# SP28038 register map
Vendor: NXP Semiconductors; Series: SP2083X; File version: 1.0
CPU: CM4 r0p1, little endian, no MPU, FPU, VTOR, 4 interrupt priority bits
Registers are 32-bit, read-write, reset 0x0 unless marked. A register's access mark holds for its fields unless they carry their own. Offsets are from the block's base; [hi:lo] are bit positions; {n}, {i} and the like mark numbered series.

## LPUART0 — Universal Asynchronous Receiver/Transmitter
Base 0x400C4000; register names take the prefix LPUART0_
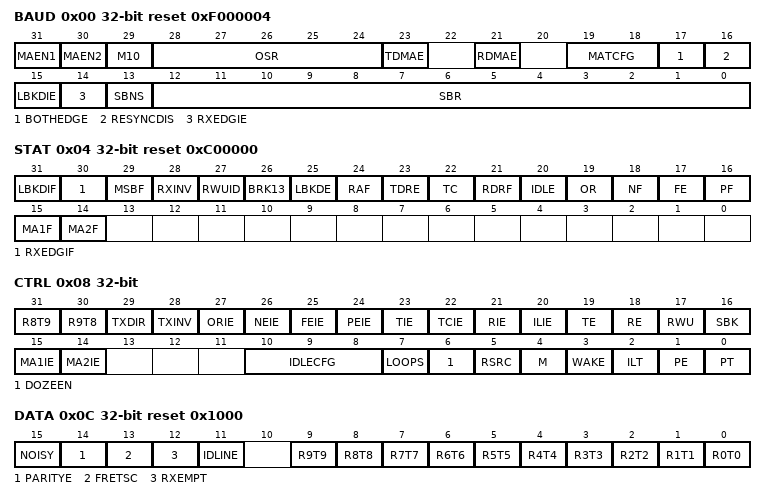
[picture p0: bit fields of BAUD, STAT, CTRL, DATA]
0x00 BAUD reset 0xF000004 — LPUART Baud Rate Register
  [31] MAEN1 — Match Address Mode Enable 1
    0=Normal operation; 1=Enables automatic address matching or data matching mode for MATCH[MA1]
  [30] MAEN2 — Match Address Mode Enable 2
    0=Normal operation; 1=Enables automatic address matching or data matching mode for MATCH[MA2]
  [29] M10 — 10-bit Mode select
    0=Receiver and transmitter use 8-bit or 9-bit data characters; 1=Receiver and transmitter use 10-bit data characters
  [28:24] OSR — Over Sampling Ratio
  [23] TDMAE — Transmitter DMA Enable
    0=DMA request disabled; 1=DMA request enabled
  [21] RDMAE — Receiver Full DMA Enable
    0=DMA request disabled; 1=DMA request enabled
  [19:18] MATCFG — Match Configuration
    0=Address Match Wakeup; 1=Idle Match Wakeup; 2=Match On and Match Off; 3=Enables RWU on Data Match and Match On/Off for transmitter CTS input
  [17] BOTHEDGE — Both Edge Sampling
    0=Receiver samples input data using the rising edge of the baud rate clock; 1=Receiver samples input data using the rising and falling edge of the baud rate clock
  [16] RESYNCDIS — Resynchronization Disable
    0=Resynchronization during received data word is supported; 1=Resynchronization during received data word is disabled
  [15] LBKDIE — LIN Break Detect Interrupt Enable
    0=Hardware interrupts from LPUART_STAT[LBKDIF] disabled (use polling); 1=Hardware interrupt requested when LPUART_STAT[LBKDIF] flag is 1
  [14] RXEDGIE — RX Input Active Edge Interrupt Enable
    0=Hardware interrupts from LPUART_STAT[RXEDGIF] disabled (use polling); 1=Hardware interrupt requested when LPUART_STAT[RXEDGIF] flag is 1
  [13] SBNS — Stop Bit Number Select
    0=One stop bit; 1=Two stop bits
  [12:0] SBR — Baud Rate Modulo Divisor.
0x04 STAT reset 0xC00000 — LPUART Status Register
  [31] LBKDIF — LIN Break Detect Interrupt Flag
    0=No LIN break character has been detected; 1=LIN break character has been detected
  [30] RXEDGIF — LPUART_RX Pin Active Edge Interrupt Flag
    0=No active edge on the receive pin has occurred; 1=An active edge on the receive pin has occurred
  [29] MSBF — MSB First
    0=LSB (bit0) is the first bit that is transmitted following the start bit. Further, the first bit received after the start bit is identified as bit0.; 1=MSB (bit9, bit8, bit7 or bit6) is the first bit that is transmitted following the start bit depending on the setting of CTRL[M], CTRL[PE] and BAUD[M10]. Further, the first bit received after the start bit is identified as bit9, bit8, bit7 or bit6 depending on the setting of CTRL[M] and CTRL[PE].
  [28] RXINV — Receive Data Inversion
    0=Receive data not inverted; 1=Receive data inverted
  [27] RWUID — Receive Wake Up Idle Detect
    0=During receive standby state (RWU = 1), the IDLE bit does not get set upon detection of an idle character. During address match wakeup, the IDLE bit does not get set when an address does not match.; 1=During receive standby state (RWU = 1), the IDLE bit gets set upon detection of an idle character. During address match wakeup, the IDLE bit does get set when an address does not match.
  [26] BRK13 — Break Character Generation Length
    0=Break character is transmitted with length of 10 bit times (if M = 0, SBNS = 0) or 11 (if M = 1, SBNS = 0 or M = 0, SBNS = 1) or 12 (if M = 1, SBNS = 1 or M10 = 1, SNBS = 0) or 13 (if M10 = 1, SNBS = 1); 1=Break character is transmitted with length of 13 bit times (if M = 0, SBNS = 0) or 14 (if M = 1, SBNS = 0 or M = 0, SBNS = 1) or 15 (if M = 1, SBNS = 1 or M10 = 1, SNBS = 0) or 16 (if M10 = 1, SNBS = 1)
  [25] LBKDE — LIN Break Detection Enable
    0=Break character is detected at length 10 bit times (if M = 0, SBNS = 0) or 11 (if M = 1, SBNS = 0 or M = 0, SBNS = 1) or 12 (if M = 1, SBNS = 1 or M10 = 1, SNBS = 0) or 13 (if M10 = 1, SNBS = 1); 1=Break character is detected at length of 11 bit times (if M = 0, SBNS = 0) or 12 (if M = 1, SBNS = 0 or M = 0, SBNS = 1) or 14 (if M = 1, SBNS = 1 or M10 = 1, SNBS = 0) or 15 (if M10 = 1, SNBS = 1)
  [24] RAF ro — Receiver Active Flag
    0=LPUART receiver idle waiting for a start bit; 1=LPUART receiver active (LPUART_RX input not idle)
  [23] TDRE ro — Transmit Data Register Empty Flag
    0=Transmit data buffer full; 1=Transmit data buffer empty
  [22] TC ro — Transmission Complete Flag
    0=Transmitter active (sending data, a preamble, or a break); 1=Transmitter idle (transmission activity complete)
  [21] RDRF ro — Receive Data Register Full Flag
    0=Receive data buffer empty; 1=Receive data buffer full
  [20] IDLE — Idle Line Flag
    0=No idle line detected; 1=Idle line was detected
  [19] OR — Receiver Overrun Flag
    0=No overrun; 1=Receive overrun (new LPUART data lost)
  [18] NF — Noise Flag
    0=No noise detected; 1=Noise detected in the received character in LPUART_DATA
  [17] FE — Framing Error Flag
    0=No framing error detected. This does not guarantee the framing is correct.; 1=Framing error
  [16] PF — Parity Error Flag
    0=No parity error; 1=Parity error
  [15] MA1F — Match 1 Flag
    0=Received data is not equal to MA1; 1=Received data is equal to MA1
  [14] MA2F — Match 2 Flag
    0=Received data is not equal to MA2; 1=Received data is equal to MA2
0x08 CTRL — LPUART Control Register
  [31] R8T9 — Receive Bit 8 / Transmit Bit 9
  [30] R9T8 — Receive Bit 9 / Transmit Bit 8
  [29] TXDIR — LPUART_TX Pin Direction in Single-Wire Mode
    0=LPUART_TX pin is an input in single-wire mode; 1=LPUART_TX pin is an output in single-wire mode
  [28] TXINV — Transmit Data Inversion
    0=Transmit data not inverted; 1=Transmit data inverted
  [27] ORIE — Overrun Interrupt Enable
    0=OR interrupts disabled; use polling; 1=Hardware interrupt requested when OR is set
  [26] NEIE — Noise Error Interrupt Enable
    0=NF interrupts disabled; use polling; 1=Hardware interrupt requested when NF is set
  [25] FEIE — Framing Error Interrupt Enable
    0=FE interrupts disabled; use polling; 1=Hardware interrupt requested when FE is set
  [24] PEIE — Parity Error Interrupt Enable
    0=PF interrupts disabled; use polling); 1=Hardware interrupt requested when PF is set
  [23] TIE — Transmit Interrupt Enable
    0=Hardware interrupts from TDRE disabled; use polling; 1=Hardware interrupt requested when TDRE flag is 1
  [22] TCIE — Transmission Complete Interrupt Enable for
    0=Hardware interrupts from TC disabled; use polling; 1=Hardware interrupt requested when TC flag is 1
  [21] RIE — Receiver Interrupt Enable
    0=Hardware interrupts from RDRF disabled; use polling; 1=Hardware interrupt requested when RDRF flag is 1
  [20] ILIE — Idle Line Interrupt Enable
    0=Hardware interrupts from IDLE disabled; use polling; 1=Hardware interrupt requested when IDLE flag is 1
  [19] TE — Transmitter Enable
    0=Transmitter disabled; 1=Transmitter enabled
  [18] RE — Receiver Enable
    0=Receiver disabled; 1=Receiver enabled
  [17] RWU — Receiver Wakeup Control
    0=Normal receiver operation; 1=LPUART receiver in standby waiting for wakeup condition
  [16] SBK — Send Break
    0=Normal transmitter operation; 1=Queue break character(s) to be sent
  [15] MA1IE — Match 1 Interrupt Enable
    0=MA1F interrupt disabled; 1=MA1F interrupt enabled
  [14] MA2IE — Match 2 Interrupt Enable
    0=MA2F interrupt disabled; 1=MA2F interrupt enabled
  [10:8] IDLECFG — Idle Configuration
    0=1 idle character; 1=2 idle characters; 2=4 idle characters; 3=8 idle characters; 4=16 idle characters; 5=32 idle characters; 6=64 idle characters; 7=128 idle characters
  [7] LOOPS — Loop Mode Select
    0=Normal operation - LPUART_RX and LPUART_TX use separate pins; 1=Loop mode or single-wire mode where transmitter outputs are internally connected to receiver input (see RSRC bit)
  [6] DOZEEN — Doze Enable
    0=LPUART is enabled in Doze mode; 1=LPUART is disabled in Doze mode
  [5] RSRC — Receiver Source Select
    0=Provided LOOPS is set, RSRC is cleared, selects internal loop back mode and the LPUART does not use the LPUART_RX pin; 1=Single-wire LPUART mode where the LPUART_TX pin is connected to the transmitter output and receiver input
  [4] M — 9-Bit or 8-Bit Mode Select
    0=Receiver and transmitter use 8-bit data characters; 1=Receiver and transmitter use 9-bit data characters
  [3] WAKE — Receiver Wakeup Method Select
    0=Configures RWU for idle-line wakeup; 1=Configures RWU with address-mark wakeup
  [2] ILT — Idle Line Type Select
    0=Idle character bit count starts after start bit; 1=Idle character bit count starts after stop bit
  [1] PE — Parity Enable
    0=No hardware parity generation or checking; 1=Parity enabled
  [0] PT — Parity Type
    0=Even parity; 1=Odd parity
0x0C DATA reset 0x1000 — LPUART Data Register
  [15] NOISY ro — The current received dataword contained in DATA[R9:R0] was received with noise.
    0=The dataword was received without noise; 1=The data was received with noise
  [14] PARITYE ro — The current received dataword contained in DATA[R9:R0] was received with a parity error.
    0=The dataword was received without a parity error; 1=The dataword was received with a parity error
  [13] FRETSC — Frame Error / Transmit Special Character
    0=The dataword was received without a frame error on read, transmit a normal character on write; 1=The dataword was received with a frame error, transmit an idle or break character on transmit
  [12] RXEMPT ro — Receive Buffer Empty
    0=Receive buffer contains valid data; 1=Receive buffer is empty, data returned on read is not valid
  [11] IDLINE ro — Idle Line
    0=Receiver was not idle before receiving this character; 1=Receiver was idle before receiving this character
  [n] R{n}T{n} (n=0..9) — Read receive data buffer {n} or write transmit data buffer {n}.
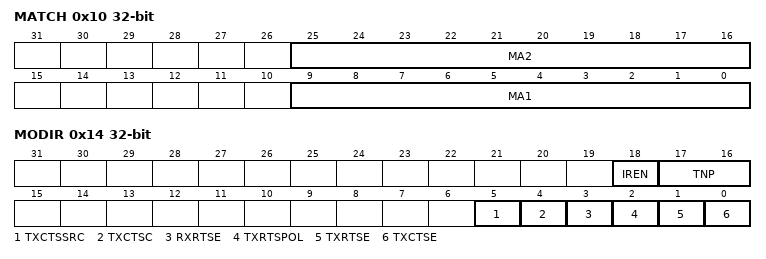
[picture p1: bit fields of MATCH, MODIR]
0x10 MATCH — LPUART Match Address Register
  [25:16] MA2 — Match Address 2
  [9:0] MA1 — Match Address 1
0x14 MODIR — LPUART Modem IrDA Register
  [18] IREN — Infrared enable
    0=IR disabled; 1=IR enabled
  [17:16] TNP — Transmitter narrow pulse
    {v}={v+1}/OSR (v=0..3)
  [5] TXCTSSRC — Transmit CTS Source
    0=CTS input is the LPUART_CTS pin; 1=CTS input is the inverted Receiver Match result
  [4] TXCTSC — Transmit CTS Configuration
    0=CTS input is sampled at the start of each character; 1=CTS input is sampled when the transmitter is idle
  [3] RXRTSE — Receiver request-to-send enable
    0=The receiver has no effect on RTS; 1=RTS is deasserted if the receiver data register is full or a start bit has been detected that would cause the receiver data register to become full. RTS is asserted if the receiver data register is not full and has not detected a start bit that would cause the receiver data register to become full.
  [2] TXRTSPOL — Transmitter request-to-send polarity
    0=Transmitter RTS is active low; 1=Transmitter RTS is active high
  [1] TXRTSE — Transmitter request-to-send enable
    0=The transmitter has no effect on RTS; 1=When a character is placed into an empty transmitter data buffer , RTS asserts one bit time before the start bit is transmitted. RTS deasserts one bit time after all characters in the transmitter data buffer and shift register are completely sent, including the last stop bit.
  [0] TXCTSE — Transmitter clear-to-send enable
    0=CTS has no effect on the transmitter; 1=Enables clear-to-send operation. The transmitter checks the state of CTS each time it is ready to send a character. If CTS is asserted, the character is sent. If CTS is deasserted, the signal TXD remains in the mark state and transmission is delayed until CTS is asserted. Changes in CTS as a character is being sent do not affect its transmission.
